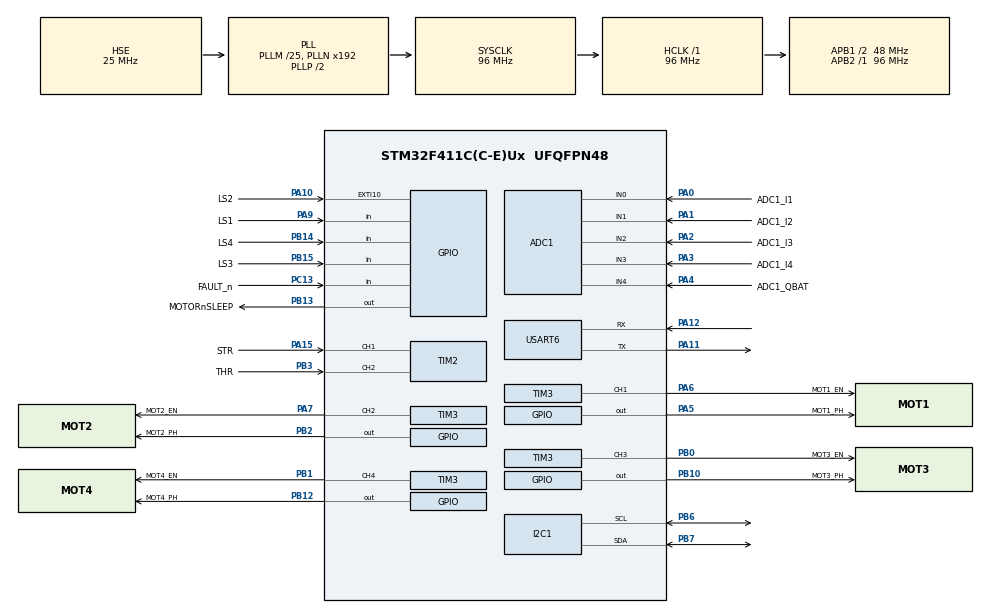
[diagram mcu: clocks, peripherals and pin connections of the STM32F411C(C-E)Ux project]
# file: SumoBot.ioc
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ADC1.Channel-1\#ChannelRegularConversion=ADC_CHANNEL_0
ADC1.NbrOfConversionFlag=1
ADC1.Rank-1\#ChannelRegularConversion=1
ADC1.SamplingTime-1\#ChannelRegularConversion=ADC_SAMPLETIME_3CYCLES
ADC1.master=1
Mcu.Family=STM32F4
Mcu.Name=STM32F411C(C-E)Ux
Mcu.Package=UFQFPN48
NVIC.PriorityGroup=NVIC_PRIORITYGROUP_4
NVIC.USART6_IRQn=true\:0\:0\:false\:false\:true\:true\:true\:true
PA0-WKUP.GPIO_Label=ADC1_I1
PA0-WKUP.Signal=ADCx_IN0
PA1.GPIO_Label=ADC1_I2
PA1.Signal=ADCx_IN1
PA10.GPIO_Label=LS2
PA10.Signal=GPXTI10
PA11.Mode=Asynchronous
PA11.Signal=USART6_TX
PA12.Mode=Asynchronous
PA12.Signal=USART6_RX
PA13.Mode=Serial_Wire
PA13.Signal=SYS_JTMS-SWDIO
PA14.Mode=Serial_Wire
PA14.Signal=SYS_JTCK-SWCLK
PA15.GPIO_Label=STR
PA15.Signal=S_TIM2_CH1_ETR
PA2.GPIO_Label=ADC1_I3
PA2.Signal=ADCx_IN2
PA3.GPIO_Label=ADC1_I4
PA3.Signal=ADCx_IN3
PA4.GPIO_Label=ADC1_QBAT
PA4.Signal=ADCx_IN4
PA5.GPIO_Label=MOT1_PH
PA5.Signal=GPIO_Output
PA6.GPIO_Label=MOT1_EN
PA6.Signal=S_TIM3_CH1
PA7.GPIO_Label=MOT2_EN
PA7.Signal=S_TIM3_CH2
PA9.GPIO_Label=LS1
PA9.Signal=GPIO_Input
PB0.GPIO_Label=MOT3_EN
PB0.Signal=S_TIM3_CH3
PB1.GPIO_Label=MOT4_EN
PB1.Signal=S_TIM3_CH4
PB10.GPIO_Label=MOT3_PH
PB10.Signal=GPIO_Output
PB12.GPIO_Label=MOT4_PH
PB12.Signal=GPIO_Output
PB13.GPIO_Label=MOTORnSLEEP
PB13.Signal=GPIO_Output
PB14.GPIO_Label=LS4
PB14.Signal=GPIO_Input
PB15.GPIO_Label=LS3
PB15.Signal=GPIO_Input
PB2.GPIO_Label=MOT2_PH
PB2.Signal=GPIO_Output
PB3.GPIO_Label=THR
PB3.Signal=S_TIM2_CH2
PB6.Mode=I2C
PB6.Signal=I2C1_SCL
PB7.Mode=I2C
PB7.Signal=I2C1_SDA
PC13-ANTI_TAMP.GPIO_Label=FAULT_n
PC13-ANTI_TAMP.Signal=GPIO_Input
PH0\ -\ OSC_IN.Mode=HSE-External-Oscillator
PH0\ -\ OSC_IN.Signal=RCC_OSC_IN
PH1\ -\ OSC_OUT.Mode=HSE-External-Oscillator
PH1\ -\ OSC_OUT.Signal=RCC_OSC_OUT
ProjectManager.HeapSize=0x200
ProjectManager.StackSize=0x400
ProjectManager.TargetToolchain=STM32CubeIDE
RCC.48MHZClocksFreq_Value=48000000
RCC.AHBFreq_Value=96000000
RCC.APB1CLKDivider=RCC_HCLK_DIV2
RCC.APB1Freq_Value=48000000
RCC.APB1TimFreq_Value=96000000
RCC.APB2Freq_Value=96000000
RCC.APB2TimFreq_Value=96000000
RCC.CortexFreq_Value=96000000
RCC.HCLKFreq_Value=96000000
RCC.HSE_VALUE=25000000
RCC.HSI_VALUE=16000000
RCC.LSE_VALUE=32768
RCC.PLLM=25
RCC.PLLSourceVirtual=RCC_PLLSOURCE_HSE
RCC.SYSCLKFreq_VALUE=96000000
RCC.SYSCLKSource=RCC_SYSCLKSOURCE_PLLCLK
RCC.VCOOutputFreq_Value=192000000
SH.ADCx_IN0.0=ADC1_IN0,IN0
SH.ADCx_IN1.0=ADC1_IN1,IN1
SH.ADCx_IN2.0=ADC1_IN2,IN2
SH.ADCx_IN3.0=ADC1_IN3,IN3
SH.ADCx_IN4.0=ADC1_IN4,IN4
SH.S_TIM2_CH1_ETR.0=TIM2_CH1,Input_Capture1_from_TI1
SH.S_TIM2_CH2.0=TIM2_CH2,Input_Capture2_from_TI2
SH.S_TIM3_CH1.0=TIM3_CH1,PWM Generation1 CH1
SH.S_TIM3_CH2.0=TIM3_CH2,PWM Generation2 CH2
SH.S_TIM3_CH3.0=TIM3_CH3,PWM Generation3 CH3
SH.S_TIM3_CH4.0=TIM3_CH4,PWM Generation4 CH4
TIM2.Channel-Input_Capture1_from_TI1=TIM_CHANNEL_1
TIM2.Channel-Input_Capture2_from_TI2=TIM_CHANNEL_2
TIM3.Channel-PWM\ Generation1\ CH1=TIM_CHANNEL_1
TIM3.Channel-PWM\ Generation2\ CH2=TIM_CHANNEL_2
TIM3.Channel-PWM\ Generation3\ CH3=TIM_CHANNEL_3
TIM3.Channel-PWM\ Generation4\ CH4=TIM_CHANNEL_4
USART6.VirtualMode=VM_ASYNC
board=custom

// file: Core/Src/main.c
/* USER CODE BEGIN Header */
/**
  ******************************************************************************
  * @file           : main.c
  * @brief          : Main program body
  ******************************************************************************
  * @attention
  *
  * Copyright (c) 2022 STMicroelectronics.
  * All rights reserved.
  *
  * This software is licensed under terms that can be found in the LICENSE file
  * in the root directory of this software component.
  * If no LICENSE file comes with this software, it is provided AS-IS.
  *
  ******************************************************************************
  */
/* USER CODE END Header */
#include "main.h"

/* USER CODE BEGIN Includes */
#include "DRV8876.h"
#include "FLYSKY_GT3A.h"
#include "string.h"
#include <stdio.h>
#include <stdlib.h>
/* USER CODE END Includes */

 ADC_HandleTypeDef hadc1;

I2C_HandleTypeDef hi2c1;

TIM_HandleTypeDef htim2;
TIM_HandleTypeDef htim3;

UART_HandleTypeDef huart6;

void SystemClock_Config(void);
static void MX_GPIO_Init(void);
static void MX_ADC1_Init(void);
static void MX_TIM3_Init(void);
static void MX_TIM2_Init(void);
static void MX_USART6_UART_Init(void);
static void MX_I2C1_Init(void);

int main(void)
{

  /* MCU Configuration--------------------------------------------------------*/

  /* Reset of all peripherals, Initializes the Flash interface and the Systick. */
  HAL_Init();

  /* USER CODE BEGIN Init */
  //Initialize Motor Structures' Parameters
   motor1 = motor(&htim3,
		   	   	  TIM_CHANNEL_1,
	   	   	 	  GPIOA,
				  GPIO_PIN_5,
				  GPIOA,
				  GPIO_PIN_
				  level);
   motor(TIM_HandleTypeDef* _htim,
   			 uint16_t			_TIM_EN,
   		  	 GPIO_TypeDef* 	 	_GPIO_PH,
   			 uint16_t			_GPIO_PH_Pin,
   			 GPIO_TypeDef*		_nSLEEP,
   			 uint16_t			_nSLEEP_Pin,
   			 int16_t            _level);
   motor2 = (Motor_t){.htim=&htim3,
	   	   	   	      .tim_ch_a=TIM_CHANNEL_3,
					  .tim_ch_b=TIM_CHANNEL_4,
					  .EN_GPIO=GPIOA,
					  .EN_Pin=GPIO_PIN_10,
					  .level=level};
   motor3 = (Motor_t){.htim=&htim3,
	   	   	   	      .tim_ch_a=TIM_CHANNEL_3,
					  .tim_ch_b=TIM_CHANNEL_4,
					  .EN_GPIO=GPIOA,
					  .EN_Pin=GPIO_PIN_10,
					  .level=level};
   //Initialize Receiver Structure Parameters
   receiver = (RC_t){.htim = &htim4,
	   	   	   	   	 .STR_CH = TIM_CHANNEL_1,
					 .THR_CH = TIM_CHANNEL_2,
					 .THR_Edge = 0,
					 .STR_Edge = 0,
					 .STR_Val1 = 0,
					 .STR_Val2=0,
					 .STR_Width=0,
					 .THR_Val1=0,
					 .THR_Val2=0,
					 .THR_Width=0};
   /* USER CODE END Init */

  /* Configure the system clock */
  SystemClock_Config();

  /* Initialize all configured peripherals */
  MX_GPIO_Init();
  MX_ADC1_Init();
  MX_TIM3_Init();
  MX_TIM2_Init();
  MX_USART6_UART_Init();
  MX_I2C1_Init();

  /* Infinite loop */
  /* USER CODE BEGIN WHILE */
  while (1)
  {
	  //Set motor1 levels based on receiver pulse widths
	  	  THR_lvl = 9.5427*receiver.THR_Width - 14495;
	  	  STR_lvl = 9.3842*receiver.STR_Width - 14118;
	  	  level_1 = THR_lvl - STR_lvl;
	  	  level_2 = THR_lvl + STR_lvl;
	  	  if ((level_1>700) | (level_1<-700))
	  	  {
	  	  set_level(&motor1, level_1);
	  	  }
	  	  if ((level_2>700) | (level_2<-700))
	  	  {
	  	  set_level(&motor2, level_2);
	  	  }

	  //Print receiver channel pulse widths at a frequency of 2Hz
	  	  current_time = HAL_GetTick();
	  	  if (current_time >= next_time)
	  	  {
	  		  mess_len = sprintf(mess, "Throttle level is %d\r\nSteering level is %d\r\n\n", receiver.THR_Width, receiver.STR_Width);
	  		  HAL_UART_Transmit(&huart2,(uint8_t*) &mess, mess_len, 10);
	  		  HAL_UART_Receive_IT(&huart2,(uint8_t*) &mess, 1);
	  		  next_time = current_time+period;
	  	  }
    /* USER CODE END WHILE */

  }
}

void SystemClock_Config(void)
{
  RCC_OscInitTypeDef RCC_OscInitStruct = {0};
  RCC_ClkInitTypeDef RCC_ClkInitStruct = {0};

  /** Configure the main internal regulator output voltage
  */
  __HAL_RCC_PWR_CLK_ENABLE();
  __HAL_PWR_VOLTAGESCALING_CONFIG(PWR_REGULATOR_VOLTAGE_SCALE1);

  /** Initializes the RCC Oscillators according to the specified parameters
  * in the RCC_OscInitTypeDef structure.
  */
  RCC_OscInitStruct.OscillatorType = RCC_OSCILLATORTYPE_HSE;
  RCC_OscInitStruct.HSEState = RCC_HSE_ON;
  RCC_OscInitStruct.PLL.PLLState = RCC_PLL_ON;
  RCC_OscInitStruct.PLL.PLLSource = RCC_PLLSOURCE_HSE;
  RCC_OscInitStruct.PLL.PLLM = 25;
  RCC_OscInitStruct.PLL.PLLN = 192;
  RCC_OscInitStruct.PLL.PLLP = RCC_PLLP_DIV2;
  RCC_OscInitStruct.PLL.PLLQ = 4;
  if (HAL_RCC_OscConfig(&RCC_OscInitStruct) != HAL_OK)
  {
    Error_Handler();
  }

  /** Initializes the CPU, AHB and APB buses clocks
  */
  RCC_ClkInitStruct.ClockType = RCC_CLOCKTYPE_HCLK|RCC_CLOCKTYPE_SYSCLK
                              |RCC_CLOCKTYPE_PCLK1|RCC_CLOCKTYPE_PCLK2;
  RCC_ClkInitStruct.SYSCLKSource = RCC_SYSCLKSOURCE_PLLCLK;
  RCC_ClkInitStruct.AHBCLKDivider = RCC_SYSCLK_DIV1;
  RCC_ClkInitStruct.APB1CLKDivider = RCC_HCLK_DIV2;
  RCC_ClkInitStruct.APB2CLKDivider = RCC_HCLK_DIV1;

  if (HAL_RCC_ClockConfig(&RCC_ClkInitStruct, FLASH_LATENCY_3) != HAL_OK)
  {
    Error_Handler();
  }
}

static void MX_ADC1_Init(void)
{

  ADC_ChannelConfTypeDef sConfig = {0};

  /** Configure the global features of the ADC (Clock, Resolution, Data Alignment and number of conversion)
  */
  hadc1.Instance = ADC1;
  hadc1.Init.ClockPrescaler = ADC_CLOCK_SYNC_PCLK_DIV4;
  hadc1.Init.Resolution = ADC_RESOLUTION_12B;
  hadc1.Init.ScanConvMode = DISABLE;
  hadc1.Init.ContinuousConvMode = DISABLE;
  hadc1.Init.DiscontinuousConvMode = DISABLE;
  hadc1.Init.ExternalTrigConvEdge = ADC_EXTERNALTRIGCONVEDGE_NONE;
  hadc1.Init.ExternalTrigConv = ADC_SOFTWARE_START;
  hadc1.Init.DataAlign = ADC_DATAALIGN_RIGHT;
  hadc1.Init.NbrOfConversion = 1;
  hadc1.Init.DMAContinuousRequests = DISABLE;
  hadc1.Init.EOCSelection = ADC_EOC_SINGLE_CONV;
  if (HAL_ADC_Init(&hadc1) != HAL_OK)
  {
    Error_Handler();
  }

  /** Configure for the selected ADC regular channel its corresponding rank in the sequencer and its sample time.
  */
  sConfig.Channel = ADC_CHANNEL_0;
  sConfig.Rank = 1;
  sConfig.SamplingTime = ADC_SAMPLETIME_3CYCLES;
  if (HAL_ADC_ConfigChannel(&hadc1, &sConfig) != HAL_OK)
  {
    Error_Handler();
  }

}

static void MX_I2C1_Init(void)
{

  hi2c1.Instance = I2C1;
  hi2c1.Init.ClockSpeed = 100000;
  hi2c1.Init.DutyCycle = I2C_DUTYCYCLE_2;
  hi2c1.Init.OwnAddress1 = 0;
  hi2c1.Init.AddressingMode = I2C_ADDRESSINGMODE_7BIT;
  hi2c1.Init.DualAddressMode = I2C_DUALADDRESS_DISABLE;
  hi2c1.Init.OwnAddress2 = 0;
  hi2c1.Init.GeneralCallMode = I2C_GENERALCALL_DISABLE;
  hi2c1.Init.NoStretchMode = I2C_NOSTRETCH_DISABLE;
  if (HAL_I2C_Init(&hi2c1) != HAL_OK)
  {
    Error_Handler();
  }

}

static void MX_TIM2_Init(void)
{

  TIM_MasterConfigTypeDef sMasterConfig = {0};
  TIM_IC_InitTypeDef sConfigIC = {0};

  htim2.Instance = TIM2;
  htim2.Init.Prescaler = 0;
  htim2.Init.CounterMode = TIM_COUNTERMODE_UP;
  htim2.Init.Period = 4294967295;
  htim2.Init.ClockDivision = TIM_CLOCKDIVISION_DIV1;
  htim2.Init.AutoReloadPreload = TIM_AUTORELOAD_PRELOAD_DISABLE;
  if (HAL_TIM_IC_Init(&htim2) != HAL_OK)
  {
    Error_Handler();
  }
  sMasterConfig.MasterOutputTrigger = TIM_TRGO_RESET;
  sMasterConfig.MasterSlaveMode = TIM_MASTERSLAVEMODE_DISABLE;
  if (HAL_TIMEx_MasterConfigSynchronization(&htim2, &sMasterConfig) != HAL_OK)
  {
    Error_Handler();
  }
  sConfigIC.ICPolarity = TIM_INPUTCHANNELPOLARITY_RISING;
  sConfigIC.ICSelection = TIM_ICSELECTION_DIRECTTI;
  sConfigIC.ICPrescaler = TIM_ICPSC_DIV1;
  sConfigIC.ICFilter = 0;
  if (HAL_TIM_IC_ConfigChannel(&htim2, &sConfigIC, TIM_CHANNEL_1) != HAL_OK)
  {
    Error_Handler();
  }
  if (HAL_TIM_IC_ConfigChannel(&htim2, &sConfigIC, TIM_CHANNEL_2) != HAL_OK)
  {
    Error_Handler();
  }

}

static void MX_TIM3_Init(void)
{

  TIM_MasterConfigTypeDef sMasterConfig = {0};
  TIM_OC_InitTypeDef sConfigOC = {0};

  htim3.Instance = TIM3;
  htim3.Init.Prescaler = 0;
  htim3.Init.CounterMode = TIM_COUNTERMODE_UP;
  htim3.Init.Period = 65535;
  htim3.Init.ClockDivision = TIM_CLOCKDIVISION_DIV1;
  htim3.Init.AutoReloadPreload = TIM_AUTORELOAD_PRELOAD_DISABLE;
  if (HAL_TIM_PWM_Init(&htim3) != HAL_OK)
  {
    Error_Handler();
  }
  sMasterConfig.MasterOutputTrigger = TIM_TRGO_RESET;
  sMasterConfig.MasterSlaveMode = TIM_MASTERSLAVEMODE_DISABLE;
  if (HAL_TIMEx_MasterConfigSynchronization(&htim3, &sMasterConfig) != HAL_OK)
  {
    Error_Handler();
  }
  sConfigOC.OCMode = TIM_OCMODE_PWM1;
  sConfigOC.Pulse = 0;
  sConfigOC.OCPolarity = TIM_OCPOLARITY_HIGH;
  sConfigOC.OCFastMode = TIM_OCFAST_DISABLE;
  if (HAL_TIM_PWM_ConfigChannel(&htim3, &sConfigOC, TIM_CHANNEL_1) != HAL_OK)
  {
    Error_Handler();
  }
  if (HAL_TIM_PWM_ConfigChannel(&htim3, &sConfigOC, TIM_CHANNEL_2) != HAL_OK)
  {
    Error_Handler();
  }
  if (HAL_TIM_PWM_ConfigChannel(&htim3, &sConfigOC, TIM_CHANNEL_3) != HAL_OK)
  {
    Error_Handler();
  }
  if (HAL_TIM_PWM_ConfigChannel(&htim3, &sConfigOC, TIM_CHANNEL_4) != HAL_OK)
  {
    Error_Handler();
  }
  HAL_TIM_MspPostInit(&htim3);

}

static void MX_USART6_UART_Init(void)
{

  huart6.Instance = USART6;
  huart6.Init.BaudRate = 115200;
  huart6.Init.WordLength = UART_WORDLENGTH_8B;
  huart6.Init.StopBits = UART_STOPBITS_1;
  huart6.Init.Parity = UART_PARITY_NONE;
  huart6.Init.Mode = UART_MODE_TX_RX;
  huart6.Init.HwFlowCtl = UART_HWCONTROL_NONE;
  huart6.Init.OverSampling = UART_OVERSAMPLING_16;
  if (HAL_UART_Init(&huart6) != HAL_OK)
  {
    Error_Handler();
  }

}

static void MX_GPIO_Init(void)
{
  GPIO_InitTypeDef GPIO_InitStruct = {0};

  /* GPIO Ports Clock Enable */
  __HAL_RCC_GPIOC_CLK_ENABLE();
  __HAL_RCC_GPIOH_CLK_ENABLE();
  __HAL_RCC_GPIOA_CLK_ENABLE();
  __HAL_RCC_GPIOB_CLK_ENABLE();

  /*Configure GPIO pin Output Level */
  HAL_GPIO_WritePin(MOT1_PH_GPIO_Port, MOT1_PH_Pin, GPIO_PIN_RESET);

  /*Configure GPIO pin Output Level */
  HAL_GPIO_WritePin(GPIOB, MOT2_PH_Pin|MOT3_PH_Pin|MOT4_PH_Pin|nSLEEP_Pin, GPIO_PIN_RESET);

  /*Configure GPIO pin : FAULT_n_Pin */
  GPIO_InitStruct.Pin = FAULT_n_Pin;
  GPIO_InitStruct.Mode = GPIO_MODE_INPUT;
  GPIO_InitStruct.Pull = GPIO_NOPULL;
  HAL_GPIO_Init(FAULT_n_GPIO_Port, &GPIO_InitStruct);

  /*Configure GPIO pin : MOT1_PH_Pin */
  GPIO_InitStruct.Pin = MOT1_PH_Pin;
  GPIO_InitStruct.Mode = GPIO_MODE_OUTPUT_PP;
  GPIO_InitStruct.Pull = GPIO_NOPULL;
  GPIO_InitStruct.Speed = GPIO_SPEED_FREQ_LOW;
  HAL_GPIO_Init(MOT1_PH_GPIO_Port, &GPIO_InitStruct);

  /*Configure GPIO pins : MOT2_PH_Pin MOT3_PH_Pin MOT4_PH_Pin nSLEEP_Pin */
  GPIO_InitStruct.Pin = MOT2_PH_Pin|MOT3_PH_Pin|MOT4_PH_Pin|nSLEEP_Pin;
  GPIO_InitStruct.Mode = GPIO_MODE_OUTPUT_PP;
  GPIO_InitStruct.Pull = GPIO_NOPULL;
  GPIO_InitStruct.Speed = GPIO_SPEED_FREQ_LOW;
  HAL_GPIO_Init(GPIOB, &GPIO_InitStruct);

  /*Configure GPIO pins : LS4_Pin LS3_Pin */
  GPIO_InitStruct.Pin = LS4_Pin|LS3_Pin;
  GPIO_InitStruct.Mode = GPIO_MODE_INPUT;
  GPIO_InitStruct.Pull = GPIO_NOPULL;
  HAL_GPIO_Init(GPIOB, &GPIO_InitStruct);

  /*Configure GPIO pin : LS1_Pin */
  GPIO_InitStruct.Pin = LS1_Pin;
  GPIO_InitStruct.Mode = GPIO_MODE_INPUT;
  GPIO_InitStruct.Pull = GPIO_NOPULL;
  HAL_GPIO_Init(LS1_GPIO_Port, &GPIO_InitStruct);

  /*Configure GPIO pin : LS2_Pin */
  GPIO_InitStruct.Pin = LS2_Pin;
  GPIO_InitStruct.Mode = GPIO_MODE_IT_RISING;
  GPIO_InitStruct.Pull = GPIO_NOPULL;
  HAL_GPIO_Init(LS2_GPIO_Port, &GPIO_InitStruct);

}

void Error_Handler(void)
{
  __disable_irq();
  while (1)
  {
  }
}
